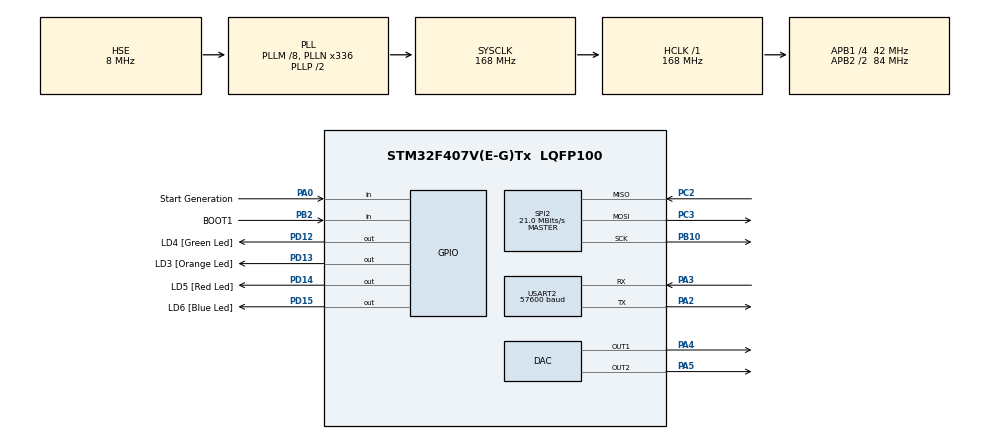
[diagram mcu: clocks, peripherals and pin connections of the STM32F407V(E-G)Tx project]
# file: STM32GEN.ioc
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Dma.DAC1.0.Direction=DMA_MEMORY_TO_PERIPH
Dma.DAC1.0.FIFOMode=DMA_FIFOMODE_DISABLE
Dma.DAC1.0.Instance=DMA1_Stream5
Dma.DAC1.0.MemDataAlignment=DMA_MDATAALIGN_HALFWORD
Dma.DAC1.0.MemInc=DMA_MINC_ENABLE
Dma.DAC1.0.Mode=DMA_NORMAL
Dma.DAC1.0.PeriphDataAlignment=DMA_PDATAALIGN_HALFWORD
Dma.DAC1.0.PeriphInc=DMA_PINC_DISABLE
Dma.DAC1.0.Priority=DMA_PRIORITY_HIGH
Dma.DAC2.1.Direction=DMA_MEMORY_TO_PERIPH
Dma.DAC2.1.FIFOMode=DMA_FIFOMODE_DISABLE
Dma.DAC2.1.Instance=DMA1_Stream6
Dma.DAC2.1.MemDataAlignment=DMA_MDATAALIGN_HALFWORD
Dma.DAC2.1.MemInc=DMA_MINC_ENABLE
Dma.DAC2.1.Mode=DMA_NORMAL
Dma.DAC2.1.PeriphDataAlignment=DMA_PDATAALIGN_HALFWORD
Dma.DAC2.1.PeriphInc=DMA_PINC_DISABLE
Dma.DAC2.1.Priority=DMA_PRIORITY_HIGH
Dma.Request0=DAC1
Dma.Request1=DAC2
Mcu.Family=STM32F4
Mcu.Name=STM32F407V(E-G)Tx
Mcu.Package=LQFP100
NVIC.DMA1_Stream5_IRQn=true\:0\:0\:false\:false\:true\:false\:true\:true
NVIC.DMA1_Stream6_IRQn=true\:0\:0\:false\:false\:true\:false\:true\:true
NVIC.PriorityGroup=NVIC_PRIORITYGROUP_4
NVIC.TIM2_IRQn=true\:15\:0\:false\:false\:true\:false\:true\:true
NVIC.TimeBase=TIM2_IRQn
NVIC.TimeBaseIP=TIM2
NVIC.USART2_IRQn=true\:0\:0\:false\:false\:true\:true\:true\:true
PA0-WKUP.GPIO_Label=Start Generation
PA0-WKUP.GPIO_PuPd=GPIO_PULLUP
PA0-WKUP.Signal=GPIO_Input
PA13.GPIO_Label=SWDIO
PA13.Mode=Serial_Wire
PA13.Signal=SYS_JTMS-SWDIO
PA14.GPIO_Label=SWCLK
PA14.Mode=Serial_Wire
PA14.Signal=SYS_JTCK-SWCLK
PA2.Mode=Asynchronous
PA2.Signal=USART2_TX
PA3.Mode=Asynchronous
PA3.Signal=USART2_RX
PA4.Signal=COMP_DAC1_group
PA5.Signal=COMP_DAC2_group
PB10.Mode=Full_Duplex_Master
PB10.Signal=SPI2_SCK
PB2.GPIO_Label=BOOT1
PB2.GPIO_Mode=GPIO_MODE_INPUT
PB2.GPIO_PuPd=GPIO_NOPULL
PB2.Signal=GPIO_Input
PC14-OSC32_IN.GPIO_Label=PC14-OSC32_IN
PC14-OSC32_IN.Mode=LSE-External-Oscillator
PC14-OSC32_IN.Signal=RCC_OSC32_IN
PC15-OSC32_OUT.GPIO_Label=PC15-OSC32_OUT
PC15-OSC32_OUT.Mode=LSE-External-Oscillator
PC15-OSC32_OUT.Signal=RCC_OSC32_OUT
PC2.Mode=Full_Duplex_Master
PC2.Signal=SPI2_MISO
PC3.Mode=Full_Duplex_Master
PC3.Signal=SPI2_MOSI
PD12.GPIO_Label=LD4 [Green Led]
PD12.GPIO_PuPd=GPIO_NOPULL
PD12.GPIO_Speed=GPIO_SPEED_FREQ_LOW
PD12.Signal=GPIO_Output
PD13.GPIO_Label=LD3 [Orange Led]
PD13.GPIO_PuPd=GPIO_NOPULL
PD13.GPIO_Speed=GPIO_SPEED_FREQ_LOW
PD13.Signal=GPIO_Output
PD14.GPIO_Label=LD5 [Red Led]
PD14.GPIO_PuPd=GPIO_NOPULL
PD14.GPIO_Speed=GPIO_SPEED_FREQ_LOW
PD14.Signal=GPIO_Output
PD15.GPIO_Label=LD6 [Blue Led]
PD15.GPIO_PuPd=GPIO_NOPULL
PD15.GPIO_Speed=GPIO_SPEED_FREQ_LOW
PD15.Signal=GPIO_Output
PH0-OSC_IN.GPIO_Label=PH0-OSC_IN
PH0-OSC_IN.Mode=HSE-External-Oscillator
PH0-OSC_IN.Signal=RCC_OSC_IN
PH1-OSC_OUT.GPIO_Label=PH1-OSC_OUT
PH1-OSC_OUT.Mode=HSE-External-Oscillator
PH1-OSC_OUT.Signal=RCC_OSC_OUT
ProjectManager.HeapSize=0x200
ProjectManager.StackSize=0x400
ProjectManager.TargetToolchain=MDK-ARM V5.32
RCC.48MHZClocksFreq_Value=48000000
RCC.AHBFreq_Value=168000000
RCC.APB1CLKDivider=RCC_HCLK_DIV4
RCC.APB1Freq_Value=42000000
RCC.APB1TimFreq_Value=84000000
RCC.APB2CLKDivider=RCC_HCLK_DIV2
RCC.APB2Freq_Value=84000000
RCC.APB2TimFreq_Value=168000000
RCC.CortexFreq_Value=168000000
RCC.HCLKFreq_Value=168000000
RCC.HSE_VALUE=8000000
RCC.HSI_VALUE=16000000
RCC.PLLM=8
RCC.PLLN=336
RCC.PLLQ=7
RCC.PLLSourceVirtual=RCC_PLLSOURCE_HSE
RCC.SYSCLKFreq_VALUE=168000000
RCC.SYSCLKSource=RCC_SYSCLKSOURCE_PLLCLK
RCC.VCOOutputFreq_Value=336000000
SH.COMP_DAC1_group.0=DAC_OUT1,DAC_OUT1
SH.COMP_DAC2_group.0=DAC_OUT2,DAC_OUT2
SPI2.CalculateBaudRate=21.0 MBits/s
SPI2.Direction=SPI_DIRECTION_2LINES
SPI2.Mode=SPI_MODE_MASTER
SPI2.VirtualType=VM_MASTER
USART2.BaudRate=57600
USART2.VirtualMode=VM_ASYNC
VP_SYS_VS_tim2.Mode=TIM2
board=STM32F407G-DISC1

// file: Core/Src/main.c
/* USER CODE BEGIN Header */
/**
  ******************************************************************************
  * @file           : main.c
  * @brief          : Main program body
  ******************************************************************************
  * @attention
  *
  * Copyright (c) 2025 STMicroelectronics.
  * All rights reserved.
  *
  * This software is licensed under terms that can be found in the LICENSE file
  * in the root directory of this software component.
  * If no LICENSE file comes with this software, it is provided AS-IS.
  *
  ******************************************************************************
  */
/* USER CODE END Header */
#include "main.h"

/* USER CODE BEGIN Includes */
#include "sendler.h" // мой сендлер
#include "command_handler.h"  // исполнитель комманд
/* USER CODE END Includes */

DAC_HandleTypeDef hdac;
DMA_HandleTypeDef hdma_dac1;
DMA_HandleTypeDef hdma_dac2;

SPI_HandleTypeDef hspi2;

UART_HandleTypeDef huart2;

void SystemClock_Config(void);
static void MX_GPIO_Init(void);
static void MX_DMA_Init(void);
static void MX_DAC_Init(void);
static void MX_SPI2_Init(void);
static void MX_USART2_UART_Init(void);
/* USER CODE BEGIN PFP */
// Прототип функции обратного вызова, которая будет вызываться при получении данных
void dataReceivedCallbackFunction(uint8_t command_code, uint8_t* data, uint16_t data_len);
/* USER CODE END PFP */

/* USER CODE BEGIN 0 */
// Функция обратного вызова, которая будет вызываться при получении данных
void dataReceivedCallbackFunction(uint8_t command_code, uint8_t* data, uint16_t data_len) {
    command_execute(command_code, data, data_len);
}
/* USER CODE END 0 */

int main(void)
{

  /* MCU Configuration--------------------------------------------------------*/

  /* Reset of all peripherals, Initializes the Flash interface and the Systick. */
  HAL_Init();

  /* Configure the system clock */
  SystemClock_Config();

  /* Initialize all configured peripherals */
  MX_GPIO_Init();
  MX_DMA_Init();
  MX_DAC_Init();
  MX_SPI2_Init();
  MX_USART2_UART_Init();
  /* USER CODE BEGIN 2 */
	Sendler.begin(57600, 0, 0x01); // 0xXX - адрес вашего устройства
  // Регистрация функции обратного вызова
  Sendler.registerCallback(dataReceivedCallbackFunction);
  /* USER CODE END 2 */

  /* Infinite loop */
  while (1)
  {

  }
}

void SystemClock_Config(void)
{
  RCC_OscInitTypeDef RCC_OscInitStruct = {0};
  RCC_ClkInitTypeDef RCC_ClkInitStruct = {0};

  /** Configure the main internal regulator output voltage
  */
  __HAL_RCC_PWR_CLK_ENABLE();
  __HAL_PWR_VOLTAGESCALING_CONFIG(PWR_REGULATOR_VOLTAGE_SCALE1);

  /** Initializes the RCC Oscillators according to the specified parameters
  * in the RCC_OscInitTypeDef structure.
  */
  RCC_OscInitStruct.OscillatorType = RCC_OSCILLATORTYPE_HSE;
  RCC_OscInitStruct.HSEState = RCC_HSE_ON;
  RCC_OscInitStruct.PLL.PLLState = RCC_PLL_ON;
  RCC_OscInitStruct.PLL.PLLSource = RCC_PLLSOURCE_HSE;
  RCC_OscInitStruct.PLL.PLLM = 8;
  RCC_OscInitStruct.PLL.PLLN = 336;
  RCC_OscInitStruct.PLL.PLLP = RCC_PLLP_DIV2;
  RCC_OscInitStruct.PLL.PLLQ = 7;
  if (HAL_RCC_OscConfig(&RCC_OscInitStruct) != HAL_OK)
  {
    Error_Handler();
  }

  /** Initializes the CPU, AHB and APB buses clocks
  */
  RCC_ClkInitStruct.ClockType = RCC_CLOCKTYPE_HCLK|RCC_CLOCKTYPE_SYSCLK
                              |RCC_CLOCKTYPE_PCLK1|RCC_CLOCKTYPE_PCLK2;
  RCC_ClkInitStruct.SYSCLKSource = RCC_SYSCLKSOURCE_PLLCLK;
  RCC_ClkInitStruct.AHBCLKDivider = RCC_SYSCLK_DIV1;
  RCC_ClkInitStruct.APB1CLKDivider = RCC_HCLK_DIV4;
  RCC_ClkInitStruct.APB2CLKDivider = RCC_HCLK_DIV2;

  if (HAL_RCC_ClockConfig(&RCC_ClkInitStruct, FLASH_LATENCY_5) != HAL_OK)
  {
    Error_Handler();
  }
}

static void MX_DAC_Init(void)
{

  DAC_ChannelConfTypeDef sConfig = {0};

  /** DAC Initialization
  */
  hdac.Instance = DAC;
  if (HAL_DAC_Init(&hdac) != HAL_OK)
  {
    Error_Handler();
  }

  /** DAC channel OUT1 config
  */
  sConfig.DAC_Trigger = DAC_TRIGGER_NONE;
  sConfig.DAC_OutputBuffer = DAC_OUTPUTBUFFER_ENABLE;
  if (HAL_DAC_ConfigChannel(&hdac, &sConfig, DAC_CHANNEL_1) != HAL_OK)
  {
    Error_Handler();
  }

  /** DAC channel OUT2 config
  */
  if (HAL_DAC_ConfigChannel(&hdac, &sConfig, DAC_CHANNEL_2) != HAL_OK)
  {
    Error_Handler();
  }

}

static void MX_SPI2_Init(void)
{

  /* SPI2 parameter configuration*/
  hspi2.Instance = SPI2;
  hspi2.Init.Mode = SPI_MODE_MASTER;
  hspi2.Init.Direction = SPI_DIRECTION_2LINES;
  hspi2.Init.DataSize = SPI_DATASIZE_8BIT;
  hspi2.Init.CLKPolarity = SPI_POLARITY_LOW;
  hspi2.Init.CLKPhase = SPI_PHASE_1EDGE;
  hspi2.Init.NSS = SPI_NSS_SOFT;
  hspi2.Init.BaudRatePrescaler = SPI_BAUDRATEPRESCALER_2;
  hspi2.Init.FirstBit = SPI_FIRSTBIT_MSB;
  hspi2.Init.TIMode = SPI_TIMODE_DISABLE;
  hspi2.Init.CRCCalculation = SPI_CRCCALCULATION_DISABLE;
  hspi2.Init.CRCPolynomial = 10;
  if (HAL_SPI_Init(&hspi2) != HAL_OK)
  {
    Error_Handler();
  }

}

static void MX_USART2_UART_Init(void)
{

  huart2.Instance = USART2;
  huart2.Init.BaudRate = 57600;
  huart2.Init.WordLength = UART_WORDLENGTH_8B;
  huart2.Init.StopBits = UART_STOPBITS_1;
  huart2.Init.Parity = UART_PARITY_NONE;
  huart2.Init.Mode = UART_MODE_TX_RX;
  huart2.Init.HwFlowCtl = UART_HWCONTROL_NONE;
  huart2.Init.OverSampling = UART_OVERSAMPLING_16;
  if (HAL_UART_Init(&huart2) != HAL_OK)
  {
    Error_Handler();
  }

}

static void MX_DMA_Init(void)
{

  /* DMA controller clock enable */
  __HAL_RCC_DMA1_CLK_ENABLE();

  /* DMA interrupt init */
  /* DMA1_Stream5_IRQn interrupt configuration */
  HAL_NVIC_SetPriority(DMA1_Stream5_IRQn, 0, 0);
  HAL_NVIC_EnableIRQ(DMA1_Stream5_IRQn);
  /* DMA1_Stream6_IRQn interrupt configuration */
  HAL_NVIC_SetPriority(DMA1_Stream6_IRQn, 0, 0);
  HAL_NVIC_EnableIRQ(DMA1_Stream6_IRQn);

}

static void MX_GPIO_Init(void)
{
  GPIO_InitTypeDef GPIO_InitStruct = {0};

  /* GPIO Ports Clock Enable */
  __HAL_RCC_GPIOC_CLK_ENABLE();
  __HAL_RCC_GPIOH_CLK_ENABLE();
  __HAL_RCC_GPIOA_CLK_ENABLE();
  __HAL_RCC_GPIOB_CLK_ENABLE();
  __HAL_RCC_GPIOD_CLK_ENABLE();

  /*Configure GPIO pin Output Level */
  HAL_GPIO_WritePin(GPIOD, LD4_Pin|LD3_Pin|LD5_Pin|LD6_Pin, GPIO_PIN_RESET);

  /*Configure GPIO pin : Start_Generation_Pin */
  GPIO_InitStruct.Pin = Start_Generation_Pin;
  GPIO_InitStruct.Mode = GPIO_MODE_INPUT;
  GPIO_InitStruct.Pull = GPIO_PULLUP;
  HAL_GPIO_Init(Start_Generation_GPIO_Port, &GPIO_InitStruct);

  /*Configure GPIO pin : BOOT1_Pin */
  GPIO_InitStruct.Pin = BOOT1_Pin;
  GPIO_InitStruct.Mode = GPIO_MODE_INPUT;
  GPIO_InitStruct.Pull = GPIO_NOPULL;
  HAL_GPIO_Init(BOOT1_GPIO_Port, &GPIO_InitStruct);

  /*Configure GPIO pins : LD4_Pin LD3_Pin LD5_Pin LD6_Pin */
  GPIO_InitStruct.Pin = LD4_Pin|LD3_Pin|LD5_Pin|LD6_Pin;
  GPIO_InitStruct.Mode = GPIO_MODE_OUTPUT_PP;
  GPIO_InitStruct.Pull = GPIO_NOPULL;
  GPIO_InitStruct.Speed = GPIO_SPEED_FREQ_LOW;
  HAL_GPIO_Init(GPIOD, &GPIO_InitStruct);

}

void HAL_TIM_PeriodElapsedCallback(TIM_HandleTypeDef *htim)
{
  if (htim->Instance == TIM2)
  {
    HAL_IncTick();
  }
}

void Error_Handler(void)
{
  __disable_irq();
  while (1)
  {
  }
}
